# S32R372 register map
Vendor: Freescale Semiconductor, Inc.; Series: Qorivva; File version: 1.6
Registers are 32-bit, read-write, reset 0x0 unless marked. A register's access mark holds for its fields unless they carry their own. Offsets are from the block's base; [hi:lo] are bit positions; {n}, {i} and the like mark numbered series; 'fields as' and 'values as' point back to an identical list.

## PFLASH — PFLASH_C55FM
Base 0xFC030000; register names take the prefix PFLASH_
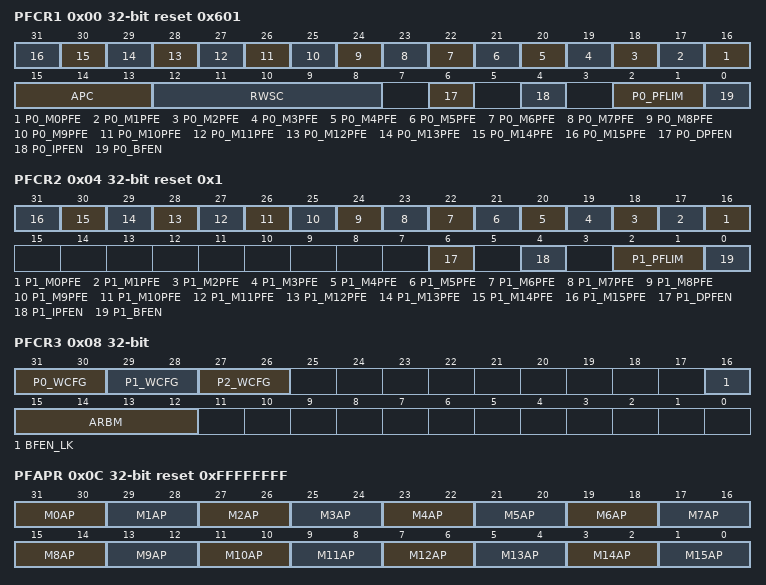
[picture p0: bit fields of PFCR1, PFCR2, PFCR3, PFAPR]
0x00 PFCR1 reset 0x601 — Platform Flash Configuration Register 1
  [n+16] P0_M{n}PFE (n=0..15) — Port0 Master {n} Prefetch enable
    0=No prefetching may be triggered by this master; 1=Prefetching may be triggered by this master
  [15:13] APC — Address Pipeline Control
    0=Pipelined access to the flash disabled; 1=A pipelined access can be initiated 1 cycle before the previous data is valid; 2=A pipelined access can be initiated 2 cycles before the previous data is valid; 3=A pipelined access can be initiated 3 cycles before the previous data is valid; 0b1xx=Pipelined access to the flash is disabled and one wait state is inserted before a subsequent access can be initiated
  [12:8] RWSC — Read Wait State Control
  [6] P0_DPFEN — Port0 Data Prefetch Enable
    0=No prefetching is triggered by a data read access; 1=Prefetching may be triggered by any data read access
  [4] P0_IPFEN — Port0 Instruction Prefetch Enable
    0=No prefetching is triggered by an instruction read access; 1=Prefetching may be triggered by any instruction read access
  [2:1] P0_PFLIM — Port0 PFlash Prefetch Limit
    0=No prefetching or buffering is performed; 1=The referenced line is prefetched on a buffer miss, that is, prefetch on miss; 2=The referenced line is prefetched on a buffer miss, or the next sequential line is prefetched on a buffer hit (if not already present), that is, prefetch on miss or hit; 3=The referenced line is prefetched on a buffer miss, or the next sequential line is prefetched on a buffer hit (if not already present), that is, prefetch on miss or hit
  [0] P0_BFEN — Port0 PFlash Line Read Buffers Enable
    0=The line read buffers are disabled from satisfying read requests, and all buffer valid bits are cleared; 1=The line read buffers are enabled to satisfy read requests on hits. Buffer valid bits may be set when the buffers are successfully filled.
0x04 PFCR2 reset 0x1 — Platform Flash Configuration Register 2
  [n+16] P1_M{n}PFE (n=0..15) — Port1 Master {n} Prefetch enable
    values as PFCR1.P0_M0PFE
  [6] P1_DPFEN — Port1 Data Prefetch Enable
    values as PFCR1.P0_DPFEN
  [4] P1_IPFEN — Port1 Instruction Prefetch Enable
    values as PFCR1.P0_IPFEN
  [2:1] P1_PFLIM — Port1 PFlash Prefetch Limit
    values as PFCR1.P0_PFLIM
  [0] P1_BFEN — Port1 PFlash Line Read Buffers Enable
    values as PFCR1.P0_BFEN
0x08 PFCR3 — Platform Flash Configuration Register 3
  [31:30] P0_WCFG — Port0 Way Configuration
    0=Both buffers in an indexed set are available for any flash access, that is, there is no partitioning of the buffers based on the access type; 2=The buffers in an indexed set are partitioned into two groups with way 0 allocated for instruction fetches and way 1 for data accesses
  [29:28] P1_WCFG — Port1 Way Configuration
    0=Both buffers are available for any flash access, that is, there is no partitioning of the buffers based on the access type; 2=The buffers are partitioned into two groups with way 0 allocated for instruction fetches and way 1 for data accesses
  [27:26] P2_WCFG — Port2 Line Buffer Configuration
    0=Both buffers are available for any flash access, that is, there is no partitioning of the buffers based on the access type; 2=The buffers are partitioned into two groups with buffer 0 allocated for instruction fetches and buffer 1 for data accesses
  [16] BFEN_LK — BFEN Lock
    0=PFCRm[Pn_BFEN] fields are R/W; 1=PFCRm[Pn_BFEN] fields are Read-only
  [15:12] ARBM — Arbitration Mode
    0=Fixed priority arbitration with AHB p0>p1>p2; 1=Fixed priority arbitration with AHB p0>p2>p1; 2=Fixed priority arbitration with AHB p2>p0>p1; 3=Fixed priority arbitration with AHB p2>p1>p0; 4=Fixed priority arbitration with AHB p1>p0>p2; 5=Fixed priority arbitration with AHB p1>p2>p0; 15=Round-robin arbitration
0x0C PFAPR reset 0xFFFFFFFF — Platform Flash Access Protection Register
  [all] fields
    0=No accesses may be performed by this master; 1=Only read accesses may be performed by this master; 2=Only write accesses may be performed by this master; 3=Both read and write accesses may be performed by this master
  [31-2n:30-2n] M{n}AP (n=0..15) — Master {n} Access Protection
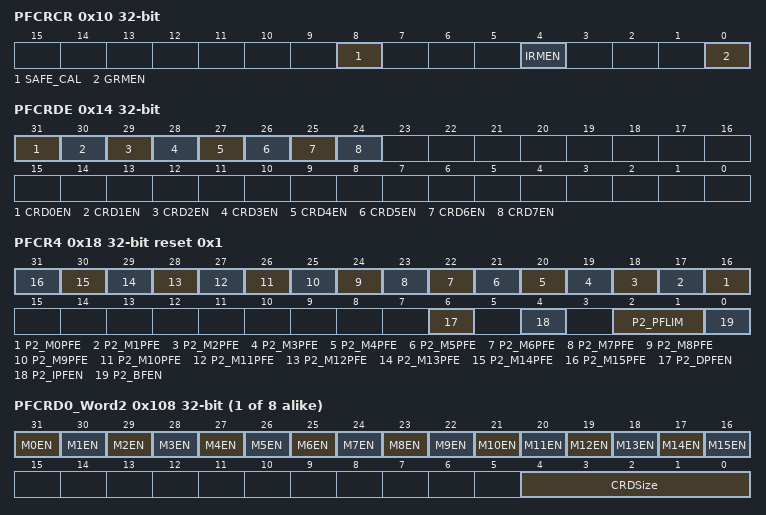
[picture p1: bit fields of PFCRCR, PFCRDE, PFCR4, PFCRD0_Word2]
0x10 PFCRCR — Platform Flash Remap Control Register
  [8] SAFE_CAL — Safe Calibration
    1=Established calibration overlay regions are considered safety-critical; 0=Established calibration overlay regions are not considered safety-critical
  [4] IRMEN — Instruction Remap
    0=Calibration remap evaluation is performed on any incoming data fetch requests only; 1=Calibration remap evaluation is performed on all incoming flash access requests - data and instruction fetches
  [0] GRMEN — Global Remap Enable
    0=Calibration remap evaluation is not performed on any incoming system flash access requests; 1=Calibration remap evaluation is performed on all incoming system flash access requests
0x14 PFCRDE — Platform Flash Remap Descriptor Enable Register
  [31-n] CRD{n}EN (n=0..7) — Calibration Remap Descriptor {n} Enable
    0=Calibration Remap Descriptor {n} invalid; 1=Calibration Remap Descriptor {n} valid
0x18 PFCR4 reset 0x1 — Platform Flash Configuration Register 4
  [n+16] P2_M{n}PFE (n=0..15) — Port2 Master {n} Prefetch enable
    values as PFCR1.P0_M0PFE
  [6] P2_DPFEN — Port2 Data Prefetch Enable
    values as PFCR1.P0_DPFEN
  [4] P2_IPFEN — Port2 Instruction Prefetch Enable
    values as PFCR1.P0_IPFEN
  [2:1] P2_PFLIM — Port2 PFlash Prefetch Limit
    values as PFCR1.P0_PFLIM
  [0] P2_BFEN — PFlash Line Read Buffers Enable
    values as PFCR1.P0_BFEN
{0x100+0x10*i} PFCRD{i}_Word0 (i=0..7) — Platform Flash Calibration Region Descriptor n Word0
  [31:4] LSTARTADDR — Logical Start Address
{0x104+0x10*i} PFCRD{i}_Word1 (i=0..7) — Platform Flash Calibration Region Descriptor n Word1
  [31:4] PSTARTADDR — Calibration Remap Descriptor n Physical Start Address - This field defines the most significant bits of the 0-modulo-size physical start byte address of the calibration remap descriptor
{0x108+0x10*i} PFCRD{i}_Word2 (i=0..7) — Platform Flash Calibration Region Descriptor n Word2
  [31-n] M{n}EN (n=0..15) — Calibration Remap Descriptor n Master x Enable - These bits determine whether calibration remapping is performed as defined by this descriptor based on the logical master ID of the requesting AHB master
    0=Calibration remap evaluation is ignored on flash access requests from Master {n} as defined by this region descriptor; 1=Calibration remap evaluation is enabled on flash access requests from Master {n} as defined by this region descriptor
  [4:0] CRDSize — Calibration Remap Descriptor n Size - This field specifies the size of the calibration remap region
    5=Region size is 32 bytes. Low-order 5 bits of LSTARTADDR and PSTARTADDR must be zero; 6=Region size is 64 bytes. Low-order 6 bits of LSTARTADDR and PSTARTADDR must be zero; 7=Region size is 128 bytes. Low-order 7 bits of LSTARTADDR and PSTARTADDR must be zero; 8=Region size is 256 bytes. Low-order 8 bits of LSTARTADDR and PSTARTADDR must be zero; 9=Region size is 512 bytes. Low-order 9 bits of LSTARTADDR and PSTARTADDR must be zero; 10=Region size is 1 KB. Low-order 10 bits of LSTARTADDR and PSTARTADDR must be zero; 11=Region size is 2 KB. Low-order 11 bits of LSTARTADDR and PSTARTADDR must be zero; 12=Region size is 4 KB. Low-order 12 bits of LSTARTADDR and PSTARTADDR must be zero; 13=Region size is 8 KB. Low-order 13 bits of LSTARTADDR and PSTARTADDR must be zero; 14=Region size is 16 KB. Low-order 14 bits of LSTARTADDR and PSTARTADDR must be zero; 15=Region size is 32 KB. Low-order 15 bits of LSTARTADDR and PSTARTADDR must be zero; 16=Region size is 64 KB. Low-order 16 bits of LSTARTADDR and PSTARTADDR must be zero; 17=Region size is 128 KB. Low-order 17 bits of LSTARTADDR and PSTARTADDR must be zero; 18=Region size is 256 KB. Low-order 18 bits of LSTARTADDR and PSTARTADDR must be zero; 19=Region size is 512 KB. Low-order 19 bits of LSTARTADDR and PSTARTADDR must be zero; 20=Region size is 1 MB. Low-order 20 bits of LSTARTADDR and PSTARTADDR must be zero; 21=Region size is 2 MB. Low-order 21 bits of LSTARTADDR and PSTARTADDR must be zero; 22=Region size is 4 MB. Low-order 22 bits of LSTARTADDR and PSTARTADDR must be zero; 23=Region size is 8 MB. Low-order 23 bits of LSTARTADDR and PSTARTADDR must be zero
